# PIC32CK1025SG00100 device description
Architecture: CORTEX-M33; Family: PIC32CK; Series: PIC32CKSG00
Registers are 32-bit, read-write, reset 0x0 unless marked. A register's access mark holds for its fields unless they carry their own. Offsets are from the block's base; [hi:lo] are bit positions; {n}, {i} and the like mark numbered series; 'fields as' and 'values as' point back to an identical list.

## PRM — Boot ROM Controller
Instances: PRM 0x4480A000
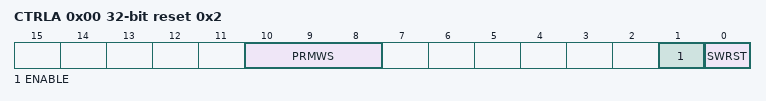
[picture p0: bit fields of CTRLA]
0x00 CTRLA reset 0x2 — CONTROL A REGISTER
  [10:8] PRMWS — ROM ACCESS TIME WAIT STATE
  [1] ENABLE — ENABLE BIT
  [0] SWRST — SOFTWARE RESET BIT

## RSTC — Reset Controller
Instances: RSTC 0x4400A000
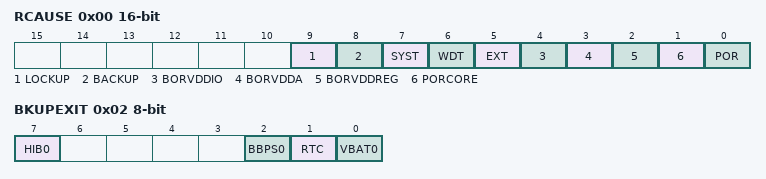
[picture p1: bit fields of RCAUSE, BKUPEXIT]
0x00 RCAUSE 16-bit ro reset not defined — Reset Cause
  [9] LOCKUP — Lockup Reset
  [8] BACKUP — Backup Reset
  [7] SYST — System Reset Request
  [6] WDT — Watchdog Reset
  [5] EXT — External Reset
  [4] BORVDDIO — Brown Out VDDIO Detector Reset
  [3] BORVDDA — Brown Out VDDA Detector Reset
  [2] BORVDDREG — Brown Out VDDREG Detector Reset
  [1] PORCORE — Brown Out CORE Detector Reset
  [0] POR — Power On Reset
0x02 BKUPEXIT 8-bit ro — Backup Exit Source. Implemented only if RSTC_BACKUP_IMPLEMENTED=1
  [7] HIB0 — Hibernate
  [2] BBPS0 — Battery Backup Power Switch
  [1] RTC — Real Timer Counter Interrupt
  [0] VBAT0 — VBAT failure in backup mode
0x04 DBGCTRL — Debug Control
  [0] LCKUPDIS — Lockup Disable

## SIG — Software Interrupt Generation
Instances: SIG 0xE000EF00, SIG_NS 0xE002EF00
0x00 STIR wo reset not defined — Software Triggered Interrupt Register
  [8:0] INTID — Interrupt ID to be pended

## SQI_DESCRIPTOR — Polaris Serial Quad Interface SIB
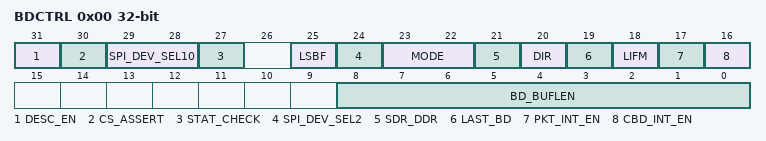
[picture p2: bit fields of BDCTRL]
0x00 BDCTRL reset not defined — Buffer Descriptor Control Register
  [31] DESC_EN — Descriptor Enable
  [30] CS_ASSERT — Chip Select Assert/Deassert
  [29:28] SPI_DEV_SEL10 — SPI Device Select bits 1:0
  [27] STAT_CHECK — Status Check
  [25] LSBF — Data format on SPI Data Lanes
  [24] SPI_DEV_SEL2 — SPI Device Select bit 2
  [23:22] MODE — Based on the mode, the controller has to transmit or receive the data in one or two or 4 lanes
  [21] SDR_DDR — SDR or DDR mode
  [20] DIR — Direction of data transfer.
  [19] LAST_BD — Last Buffer Descriptors.
  [18] LIFM — Indicates last data of the packet.
  [17] PKT_INT_EN — Generate Interrupt after processing the current buffer descriptor, if it is the end of the packet.
  [16] CBD_INT_EN — Generate Interrupt after processing the current buffer descriptor
  [8:0] BD_BUFLEN — Buffer Descriptor Length
0x04 BDSTATUS reset not defined — Buffer Descriptor Status Register
0x08 BDADDR reset not defined — Buffer Descriptor Address Register
0x0C BDNXTPTR reset not defined — Buffer Descriptor Next Pointer Register

## SysTick — SysTick Timer
Instances: SysTick 0xE000E010, SysTick_NS 0xE002E010
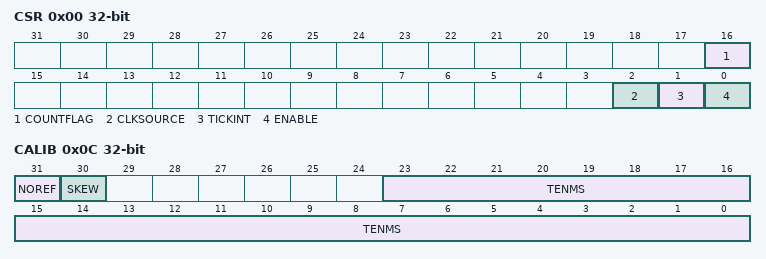
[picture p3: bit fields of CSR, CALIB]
0x00 CSR reset not defined — SysTick Control and Status Register
  [16] COUNTFLAG
  [2] CLKSOURCE — Clock source
  [1] TICKINT — Tick interrupt
  [0] ENABLE — SysTick enable
0x04 RVR reset not defined — SysTick Reload Value Register
  [24] RELOAD — Counter reload value
0x08 CVR reset not defined — SysTick Current Value Register
  [24] CURRENT — Current counter value
0x0C CALIB ro reset not defined — SysTick Calibration Value Register
  [31] NOREF — No reference
  [30] SKEW
  [23:0] TENMS — Ten milliseconds

## TRAM — TrustRAM
Instances: TRAM 0x4401E000
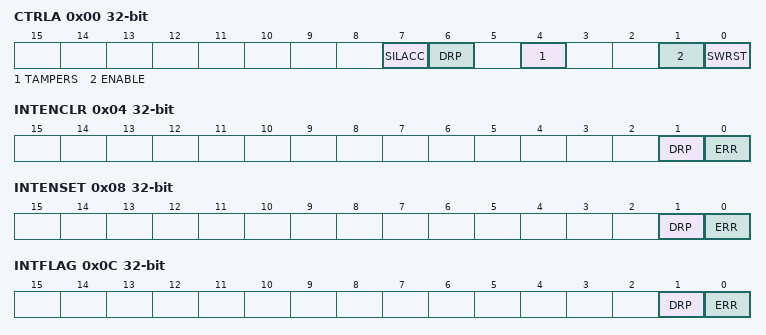
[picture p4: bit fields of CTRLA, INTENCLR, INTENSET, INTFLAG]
0x00 CTRLA — Control
  [7] SILACC — Silent Access
  [6] DRP — Data Remanence Prevention
  [4] TAMPERS — Tamper Erase
  [1] ENABLE
  [0] SWRST — Software Reset
0x04 INTENCLR (atomic clear) — Interrupt Enable Clear
  [1] DRP — Data Remanence Prevention Ended Interrupt Enable
  [0] ERR — TrustRAM Readout Error Interrupt Enable
0x08 INTENSET (atomic set) — Interrupt Enable Set
  fields as INTENCLR
0x0C INTFLAG (atomic clear) — Interrupt Flag Status and Clear
  [1] DRP — Data Remanence Prevention Ended
  [0] ERR — TrustRAM Readout Error
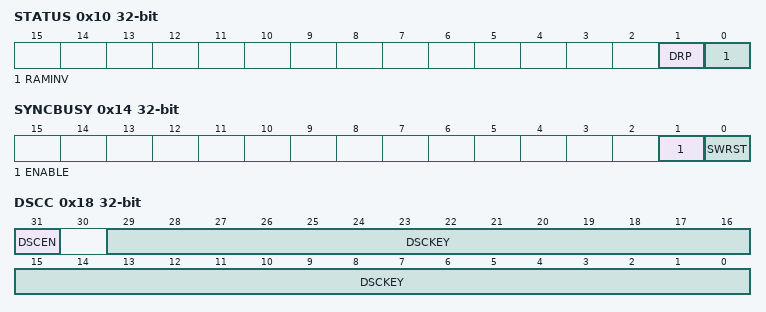
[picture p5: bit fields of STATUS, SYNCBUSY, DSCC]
0x10 STATUS ro
  [1] DRP — Data Remanence Prevention Ongoing
  [0] RAMINV — RAM Inversion Bit
0x14 SYNCBUSY ro — Synchronization Busy Status
  [1] ENABLE — Enable Busy
  [0] SWRST — Software Reset Busy
0x18 DSCC wo — Data Scramble Control
  [31] DSCEN — Data Scramble Enable
  [29:0] DSCKEY — Data Scramble Key
0x1C PERMW wo — Permutation Write
  [2:0] DATA — Permutation Scrambler Data Input
0x20 PERMR ro — Permutation Read
  [2:0] DATA — Permutation Scrambler Data Output
{0x1000+4i} RAM[{i}] (i=0..2047) — TrustRAM
  [31:0] DATA — Trust RAM Data

## Notices in the file
Copyright (c) 2021 Microchip Technology Inc.
SPDX-License-Identifier: Apache-2.0
Licensed under the Apache License, Version 2.0 (the "License");
you may not use this file except in compliance with the License.
You may obtain a copy of the License at
http://www.apache.org/licenses/LICENSE-2.0
Unless required by applicable law or agreed to in writing, software
distributed under the License is distributed on an "AS IS" BASIS,
WITHOUT WARRANTIES OR CONDITIONS OF ANY KIND, either express or implied.
See the License for the specific language governing permissions and
limitations under the License.
